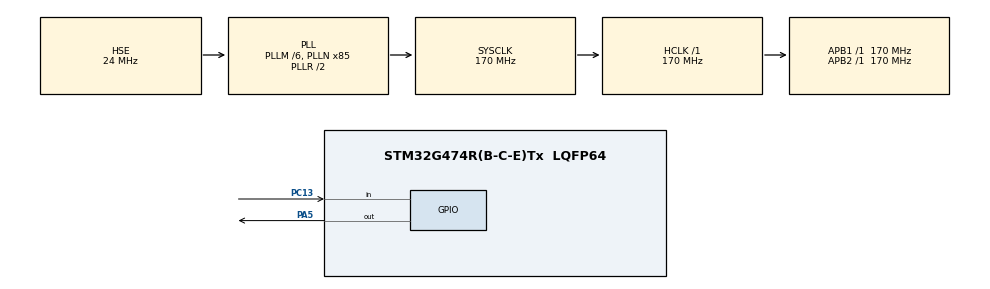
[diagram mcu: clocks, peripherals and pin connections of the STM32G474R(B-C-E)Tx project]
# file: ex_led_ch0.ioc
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Mcu.Family=STM32G4
RCC.PLLSourceVirtual=RCC_PLLSOURCE_HSE
RCC.CortexFreq_Value=170000000
PC13.Signal=GPIO_Input
RCC.EXTERNAL_CLOCK_VALUE=12288000
RCC.SYSCLKSource=RCC_SYSCLKSOURCE_PLLCLK
ProjectManager.StackSize=0x400
PA13.Signal=SYS_JTMS-SWDIO
ProjectManager.TargetToolchain=STM32CubeIDE
RCC.HCLKFreq_Value=170000000
RCC.APB2TimFreq_Value=170000000
RCC.USBFreq_Value=170000000
RCC.LSE_VALUE=32768
RCC.AHBFreq_Value=170000000
PF0-OSC_IN.Mode=HSE-External-Oscillator
PA5.Signal=GPIO_Output
RCC.HSE_VALUE=24000000
board=custom
RCC.VCOOutputFreq_Value=340000000
RCC.ADC12Freq_Value=170000000
RCC.ADC345Freq_Value=170000000
RCC.APB2Freq_Value=170000000
PA14.Mode=Serial_Wire
VP_SYS_VS_DBSignals.Mode=DisableDeadBatterySignals
PA13.Mode=Serial_Wire
Mcu.Name=STM32G474R(B-C-E)Tx
RCC.SYSCLKFreq_VALUE=170000000
Mcu.Package=LQFP64
PA14.Signal=SYS_JTCK-SWCLK
ProjectManager.HeapSize=0x200
RCC.HSI_VALUE=16000000
NVIC.PriorityGroup=NVIC_PRIORITYGROUP_4
RCC.PLLM=RCC_PLLM_DIV6
RCC.PLLN=85
RCC.APB1TimFreq_Value=170000000
PF0-OSC_IN.Signal=RCC_OSC_IN
PF1-OSC_OUT.Mode=HSE-External-Oscillator
RCC.APB1Freq_Value=170000000
PF1-OSC_OUT.Signal=RCC_OSC_OUT
RCC.HSI48_VALUE=48000000

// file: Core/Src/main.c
/* USER CODE BEGIN Header */
/**
  ******************************************************************************
  * @file           : main.c
  * @brief          : Main program body
  ******************************************************************************
  * @attention
  *
  * <h2><center>&copy; Copyright (c) 2022 STMicroelectronics.
  * All rights reserved.</center></h2>
  *
  * This software component is licensed by ST under BSD 3-Clause license,
  * the "License"; You may not use this file except in compliance with the
  * License. You may obtain a copy of the License at:
  *                        opensource.org/licenses/BSD-3-Clause
  *
  ******************************************************************************
  */
/* USER CODE END Header */
#include "main.h"

void SystemClock_Config(void);
static void MX_GPIO_Init(void);

int main(void)
{

  /* MCU Configuration--------------------------------------------------------*/

  /* Reset of all peripherals, Initializes the Flash interface and the Systick. */
  HAL_Init();

  /* Configure the system clock */
  SystemClock_Config();

  /* Initialize all configured peripherals */
  MX_GPIO_Init();

  /* Infinite loop */
  while (1)
  {

    /* USER CODE BEGIN 3 */
	  if ( HAL_GPIO_ReadPin(GPIOC, GPIO_PIN_13)) 				// 判断按键是否按下:1按下,0释放
	  	 HAL_GPIO_WritePin(GPIOA, GPIO_PIN_5,GPIO_PIN_SET); 		//按下亮
	  else HAL_GPIO_WritePin(GPIOA, GPIO_PIN_5,GPIO_PIN_RESET);		//释放灭

  }
  /* USER CODE END 3 */
}

void SystemClock_Config(void)
{
  RCC_OscInitTypeDef RCC_OscInitStruct = {0};
  RCC_ClkInitTypeDef RCC_ClkInitStruct = {0};

  /** Configure the main internal regulator output voltage
  */
  HAL_PWREx_ControlVoltageScaling(PWR_REGULATOR_VOLTAGE_SCALE1_BOOST);
  /** Initializes the RCC Oscillators according to the specified parameters
  * in the RCC_OscInitTypeDef structure.
  */
  RCC_OscInitStruct.OscillatorType = RCC_OSCILLATORTYPE_HSE;
  RCC_OscInitStruct.HSEState = RCC_HSE_ON;
  RCC_OscInitStruct.PLL.PLLState = RCC_PLL_ON;
  RCC_OscInitStruct.PLL.PLLSource = RCC_PLLSOURCE_HSE;
  RCC_OscInitStruct.PLL.PLLM = RCC_PLLM_DIV6;
  RCC_OscInitStruct.PLL.PLLN = 85;
  RCC_OscInitStruct.PLL.PLLP = RCC_PLLP_DIV2;
  RCC_OscInitStruct.PLL.PLLQ = RCC_PLLQ_DIV2;
  RCC_OscInitStruct.PLL.PLLR = RCC_PLLR_DIV2;
  if (HAL_RCC_OscConfig(&RCC_OscInitStruct) != HAL_OK)
  {
    Error_Handler();
  }
  /** Initializes the CPU, AHB and APB buses clocks
  */
  RCC_ClkInitStruct.ClockType = RCC_CLOCKTYPE_HCLK|RCC_CLOCKTYPE_SYSCLK
                              |RCC_CLOCKTYPE_PCLK1|RCC_CLOCKTYPE_PCLK2;
  RCC_ClkInitStruct.SYSCLKSource = RCC_SYSCLKSOURCE_PLLCLK;
  RCC_ClkInitStruct.AHBCLKDivider = RCC_SYSCLK_DIV1;
  RCC_ClkInitStruct.APB1CLKDivider = RCC_HCLK_DIV1;
  RCC_ClkInitStruct.APB2CLKDivider = RCC_HCLK_DIV1;

  if (HAL_RCC_ClockConfig(&RCC_ClkInitStruct, FLASH_LATENCY_4) != HAL_OK)
  {
    Error_Handler();
  }
}

static void MX_GPIO_Init(void)
{
  GPIO_InitTypeDef GPIO_InitStruct = {0};

  /* GPIO Ports Clock Enable */
  __HAL_RCC_GPIOC_CLK_ENABLE();
  __HAL_RCC_GPIOF_CLK_ENABLE();
  __HAL_RCC_GPIOA_CLK_ENABLE();

  /*Configure GPIO pin Output Level */
  HAL_GPIO_WritePin(GPIOA, GPIO_PIN_5, GPIO_PIN_RESET);

  /*Configure GPIO pin : PC13 */
  GPIO_InitStruct.Pin = GPIO_PIN_13;
  GPIO_InitStruct.Mode = GPIO_MODE_INPUT;
  GPIO_InitStruct.Pull = GPIO_NOPULL;
  HAL_GPIO_Init(GPIOC, &GPIO_InitStruct);

  /*Configure GPIO pin : PA5 */
  GPIO_InitStruct.Pin = GPIO_PIN_5;
  GPIO_InitStruct.Mode = GPIO_MODE_OUTPUT_PP;
  GPIO_InitStruct.Pull = GPIO_NOPULL;
  GPIO_InitStruct.Speed = GPIO_SPEED_FREQ_LOW;
  HAL_GPIO_Init(GPIOA, &GPIO_InitStruct);

}

void Error_Handler(void)
{
  __disable_irq();
  while (1)
  {
  }
}

/************************ (C) COPYRIGHT STMicroelectronics *****END OF FILE****/
